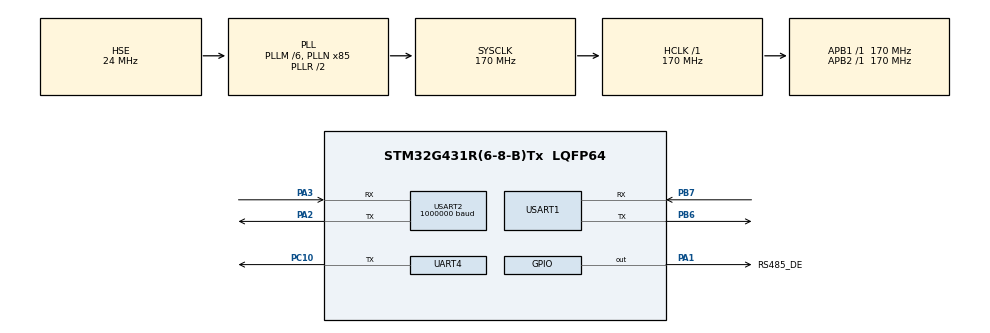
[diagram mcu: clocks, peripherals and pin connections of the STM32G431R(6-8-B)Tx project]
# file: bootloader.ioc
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Dma.Request0=USART2_RX
Dma.USART2_RX.0.Direction=DMA_PERIPH_TO_MEMORY
Dma.USART2_RX.0.EventEnable=DISABLE
Dma.USART2_RX.0.Instance=DMA1_Channel1
Dma.USART2_RX.0.MemDataAlignment=DMA_MDATAALIGN_BYTE
Dma.USART2_RX.0.MemInc=DMA_MINC_ENABLE
Dma.USART2_RX.0.Mode=DMA_NORMAL
Dma.USART2_RX.0.PeriphDataAlignment=DMA_PDATAALIGN_BYTE
Dma.USART2_RX.0.PeriphInc=DMA_PINC_DISABLE
Dma.USART2_RX.0.Polarity=HAL_DMAMUX_REQ_GEN_RISING
Dma.USART2_RX.0.Priority=DMA_PRIORITY_LOW
Dma.USART2_RX.0.RequestNumber=1
Dma.USART2_RX.0.SignalID=NONE
Dma.USART2_RX.0.SyncEnable=DISABLE
Dma.USART2_RX.0.SyncPolarity=HAL_DMAMUX_SYNC_NO_EVENT
Dma.USART2_RX.0.SyncRequestNumber=1
Dma.USART2_RX.0.SyncSignalID=NONE
Mcu.Family=STM32G4
Mcu.Name=STM32G431R(6-8-B)Tx
Mcu.Package=LQFP64
NVIC.DMA1_Channel1_IRQn=true\:0\:0\:false\:false\:true\:false\:true
NVIC.PriorityGroup=NVIC_PRIORITYGROUP_4
NVIC.USART2_IRQn=true\:0\:0\:false\:false\:true\:true\:true
PA1.GPIO_Label=RS485_DE
PA1.GPIO_Speed=GPIO_SPEED_FREQ_HIGH
PA1.Signal=GPIO_Output
PA13.Mode=Serial_Wire
PA13.Signal=SYS_JTMS-SWDIO
PA14.Mode=Serial_Wire
PA14.Signal=SYS_JTCK-SWCLK
PA2.Mode=Asynchronous
PA2.Signal=USART2_TX
PA3.Mode=Asynchronous
PA3.Signal=USART2_RX
PB6.Mode=Asynchronous
PB6.Signal=USART1_TX
PB7.Mode=Asynchronous
PB7.Signal=USART1_RX
PC10.Mode=Asynchronous
PC10.Signal=UART4_TX
PF0-OSC_IN.Mode=HSE-External-Oscillator
PF0-OSC_IN.Signal=RCC_OSC_IN
PF1-OSC_OUT.Mode=HSE-External-Oscillator
PF1-OSC_OUT.Signal=RCC_OSC_OUT
ProjectManager.HeapSize=0x200
ProjectManager.StackSize=0x400
ProjectManager.TargetToolchain=MDK-ARM V5.32
RCC.ADC12Freq_Value=170000000
RCC.AHBFreq_Value=170000000
RCC.APB1Freq_Value=170000000
RCC.APB1TimFreq_Value=170000000
RCC.APB2Freq_Value=170000000
RCC.APB2TimFreq_Value=170000000
RCC.CortexFreq_Value=170000000
RCC.EXTERNAL_CLOCK_VALUE=12288000
RCC.HCLKFreq_Value=170000000
RCC.HSE_VALUE=24000000
RCC.HSI48_VALUE=48000000
RCC.HSI_VALUE=16000000
RCC.LSE_VALUE=32768
RCC.PLLM=RCC_PLLM_DIV6
RCC.PLLN=85
RCC.PLLSourceVirtual=RCC_PLLSOURCE_HSE
RCC.SYSCLKFreq_VALUE=170000000
RCC.SYSCLKSource=RCC_SYSCLKSOURCE_PLLCLK
RCC.USBFreq_Value=170000000
RCC.VCOOutputFreq_Value=340000000
USART1.VirtualMode-Asynchronous=VM_ASYNC
USART2.BaudRate=1000000
USART2.VirtualMode-Asynchronous=VM_ASYNC
VP_SYS_VS_DBSignals.Mode=DisableDeadBatterySignals
board=custom

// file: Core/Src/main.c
/* USER CODE BEGIN Header */
/**
  ******************************************************************************
  * @file           : main.c
  * @brief          : Main program body
  ******************************************************************************
  * @attention
  *
  * <h2><center>&copy; Copyright (c) 2026 STMicroelectronics.
  * All rights reserved.</center></h2>
  *
  * This software component is licensed by ST under BSD 3-Clause license,
  * the "License"; You may not use this file except in compliance with the
  * License. You may obtain a copy of the License at:
  *                        opensource.org/licenses/BSD-3-Clause
  *
  ******************************************************************************
  */
/* USER CODE END Header */
#include "main.h"
#include "dma.h"
#include "usart.h"
#include "gpio.h"

/* USER CODE BEGIN Includes */
#include "modbus_port.h"
#include "upgrade.h"
#include "boot_log.h"
/* USER CODE END Includes */

/* USER CODE BEGIN PV */
volatile uint32_t errstate = 0u;

/* USER CODE END PV */

void SystemClock_Config(void);

int main(void)
{

  /* MCU Configuration--------------------------------------------------------*/

  /* Reset of all peripherals, Initializes the Flash interface and the Systick. */
  HAL_Init();

  /* Configure the system clock */
  SystemClock_Config();

  /* Initialize all configured peripherals */
  MX_GPIO_Init();
  MX_DMA_Init();
  MX_USART2_UART_Init();
  MX_USART1_UART_Init();
  /* USER CODE BEGIN 2 */
  {
    HAL_StatusTypeDef status = Modbus_StartReceive();
    if(status != HAL_OK)
      /* 0x2001: 初次启动 DMA/DWT 失败；查�? SystemCoreClock、DWT->CTRL �? huart2�? */
      ERROR_HANDLER_FROM(ERROR_ID_BOOT_RX_START, "Initial USART2 DMA/DWT receive start", status);
  }
  boot_log_start();
  Upgrade_Init();
  /* USER CODE END 2 */

  /* Infinite loop */
  while (1)
  {

    /* USER CODE BEGIN 3 */
    modbusdeal();
    Upgrade_Poll();
  }
  /* USER CODE END 3 */
}

void SystemClock_Config(void)
{
  RCC_OscInitTypeDef RCC_OscInitStruct = {0};
  RCC_ClkInitTypeDef RCC_ClkInitStruct = {0};
  RCC_PeriphCLKInitTypeDef PeriphClkInit = {0};

  /** Configure the main internal regulator output voltage
  */
  HAL_PWREx_ControlVoltageScaling(PWR_REGULATOR_VOLTAGE_SCALE1_BOOST);
  /** Initializes the RCC Oscillators according to the specified parameters
  * in the RCC_OscInitTypeDef structure.
  */
  RCC_OscInitStruct.OscillatorType = RCC_OSCILLATORTYPE_HSE;
  RCC_OscInitStruct.HSEState = RCC_HSE_ON;
  RCC_OscInitStruct.PLL.PLLState = RCC_PLL_ON;
  RCC_OscInitStruct.PLL.PLLSource = RCC_PLLSOURCE_HSE;
  RCC_OscInitStruct.PLL.PLLM = RCC_PLLM_DIV6;
  RCC_OscInitStruct.PLL.PLLN = 85;
  RCC_OscInitStruct.PLL.PLLP = RCC_PLLP_DIV2;
  RCC_OscInitStruct.PLL.PLLQ = RCC_PLLQ_DIV2;
  RCC_OscInitStruct.PLL.PLLR = RCC_PLLR_DIV2;
  if (HAL_RCC_OscConfig(&RCC_OscInitStruct) != HAL_OK)
  {
    Error_Handler();
  }
  /** Initializes the CPU, AHB and APB buses clocks
  */
  RCC_ClkInitStruct.ClockType = RCC_CLOCKTYPE_HCLK|RCC_CLOCKTYPE_SYSCLK
                              |RCC_CLOCKTYPE_PCLK1|RCC_CLOCKTYPE_PCLK2;
  RCC_ClkInitStruct.SYSCLKSource = RCC_SYSCLKSOURCE_PLLCLK;
  RCC_ClkInitStruct.AHBCLKDivider = RCC_SYSCLK_DIV1;
  RCC_ClkInitStruct.APB1CLKDivider = RCC_HCLK_DIV1;
  RCC_ClkInitStruct.APB2CLKDivider = RCC_HCLK_DIV1;

  if (HAL_RCC_ClockConfig(&RCC_ClkInitStruct, FLASH_LATENCY_4) != HAL_OK)
  {
    Error_Handler();
  }
  /** Initializes the peripherals clocks
  */
  PeriphClkInit.PeriphClockSelection = RCC_PERIPHCLK_USART1|RCC_PERIPHCLK_USART2;
  PeriphClkInit.Usart1ClockSelection = RCC_USART1CLKSOURCE_PCLK2;
  PeriphClkInit.Usart2ClockSelection = RCC_USART2CLKSOURCE_PCLK1;
  if (HAL_RCCEx_PeriphCLKConfig(&PeriphClkInit) != HAL_OK)
  {
    Error_Handler();
  }
}

void Error_Handler(void)
{
  /* USER CODE BEGIN Error_Handler_Debug */
  /* �? Keil Watch 展开 g_error_trace 查看首次错误的来源和 detail�? */
  Error_TraceRecord(ERROR_ID_UNMARKED, "Direct Error_Handler without source tag", 0,
                    __FILE__, __LINE__, __func__);
  /* User can add his own implementation to report the HAL error return state */
  __disable_irq();
  while (1)
  {
		errstate=1;
  }
  /* USER CODE END Error_Handler_Debug */
}

/************************ (C) COPYRIGHT STMicroelectronics *****END OF FILE****/
